VERSION ""

BS_:
BU_:

// =====================================================
// TX14 / CAN ID 0x11C / 284
// =====================================================
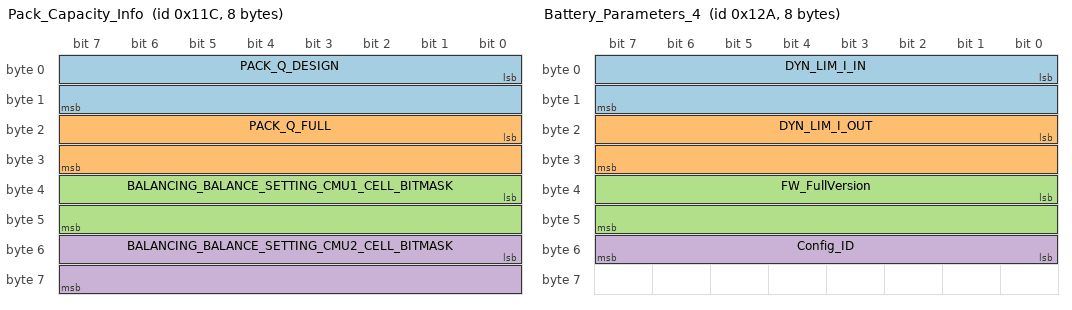
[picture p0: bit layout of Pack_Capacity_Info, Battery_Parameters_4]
BO_ 284 Pack_Capacity_Info: 8 Vector__XXX
 SG_ PACK_Q_DESIGN : 0|16@1+ (0.1,0) [0|180] "Ah" Vector__XXX
 SG_ PACK_Q_FULL   : 16|16@1+ (0.1,0) [0|180] "Ah" Vector__XXX
 SG_ BALANCING_BALANCE_SETTING_CMU1_CELL_BITMASK : 32|16@1+ (0.1,0) [0|6553.5] "mV" Vector__XXX
 SG_ BALANCING_BALANCE_SETTING_CMU2_CELL_BITMASK : 48|16@1+ (0.1,0) [0|6553.5] "mV" Vector__XXX

// =====================================================
// TX11 / CAN ID 0x12A / 298
// =====================================================
BO_ 298 Battery_Parameters_4: 8 Vector__XXX
 SG_ DYN_LIM_I_IN   : 0|16@1+ (0.1,0) [0|6553.5] "A" Vector__XXX
 SG_ DYN_LIM_I_OUT  : 16|16@1+ (0.1,0) [0|6553.5] "A" Vector__XXX
 SG_ FW_FullVersion: 32|16@1+ (1,0) [0|65535] "" Vector__XXX
 SG_ Config_ID     : 48|8@1+  (1,0) [0|255] "" Vector__XXX

// =====================================================
// TX9 / CAN ID 0x118 / 280
// =====================================================
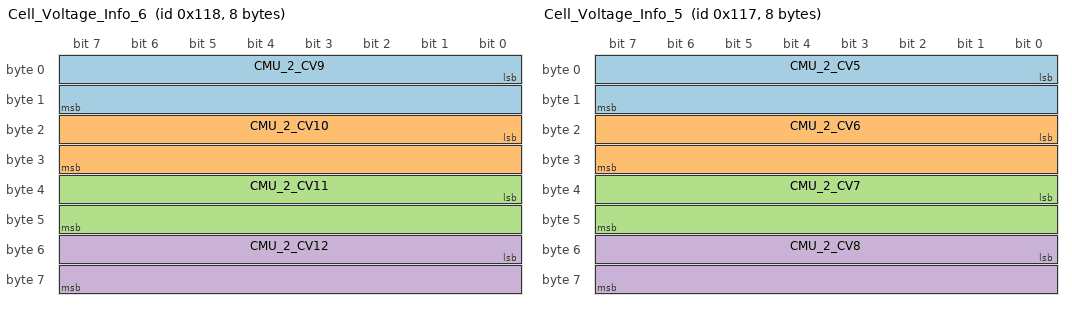
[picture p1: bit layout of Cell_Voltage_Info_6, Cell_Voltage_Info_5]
BO_ 280 Cell_Voltage_Info_6: 8 Vector__XXX
 SG_ CMU_2_CV9  : 0|16@1+ (0.1,0) [0|6553.5] "mV" Vector__XXX
 SG_ CMU_2_CV10 : 16|16@1+ (0.1,0) [0|6553.5] "mV" Vector__XXX
 SG_ CMU_2_CV11 : 32|16@1+ (0.1,0) [0|6553.5] "mV" Vector__XXX
 SG_ CMU_2_CV12 : 48|16@1+ (0.1,0) [0|6553.5] "mV" Vector__XXX

// =====================================================
// TX8 / CAN ID 0x117 / 279
// =====================================================
BO_ 279 Cell_Voltage_Info_5: 8 Vector__XXX
 SG_ CMU_2_CV5 : 0|16@1+ (0.1,0) [0|6553.5] "mV" Vector__XXX
 SG_ CMU_2_CV6 : 16|16@1+ (0.1,0) [0|6553.5] "mV" Vector__XXX
 SG_ CMU_2_CV7 : 32|16@1+ (0.1,0) [0|6553.5] "mV" Vector__XXX
 SG_ CMU_2_CV8 : 48|16@1+ (0.1,0) [0|6553.5] "mV" Vector__XXX

// =====================================================
// TX7 / CAN ID 0x116 / 278
// =====================================================
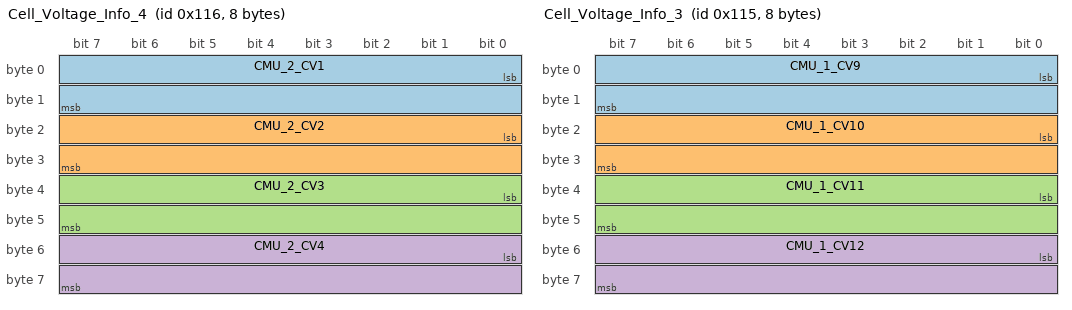
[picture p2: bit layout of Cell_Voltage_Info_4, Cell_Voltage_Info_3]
BO_ 278 Cell_Voltage_Info_4: 8 Vector__XXX
 SG_ CMU_2_CV1 : 0|16@1+ (0.1,0) [0|6553.5] "mV" Vector__XXX
 SG_ CMU_2_CV2 : 16|16@1+ (0.1,0) [0|6553.5] "mV" Vector__XXX
 SG_ CMU_2_CV3 : 32|16@1+ (0.1,0) [0|6553.5] "mV" Vector__XXX
 SG_ CMU_2_CV4 : 48|16@1+ (0.1,0) [0|6553.5] "mV" Vector__XXX

// =====================================================
// TX6 / CAN ID 0x115 / 277
// =====================================================
BO_ 277 Cell_Voltage_Info_3: 8 Vector__XXX
 SG_ CMU_1_CV9  : 0|16@1+ (0.1,0) [0|6553.5] "mV" Vector__XXX
 SG_ CMU_1_CV10 : 16|16@1+ (0.1,0) [0|6553.5] "mV" Vector__XXX
 SG_ CMU_1_CV11 : 32|16@1+ (0.1,0) [0|6553.5] "mV" Vector__XXX
 SG_ CMU_1_CV12 : 48|16@1+ (0.1,0) [0|6553.5] "mV" Vector__XXX

// =====================================================
// TX5 / CAN ID 0x114 / 276
// =====================================================
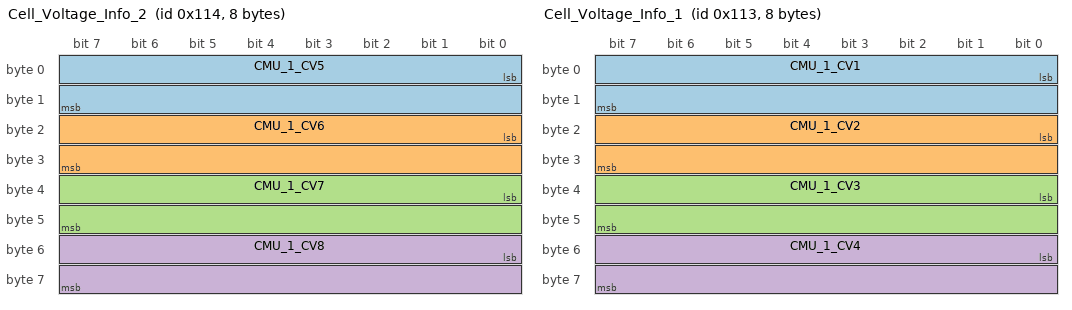
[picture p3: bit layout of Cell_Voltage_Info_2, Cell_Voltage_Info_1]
BO_ 276 Cell_Voltage_Info_2: 8 Vector__XXX
 SG_ CMU_1_CV5 : 0|16@1+ (0.1,0) [0|6553.5] "mV" Vector__XXX
 SG_ CMU_1_CV6 : 16|16@1+ (0.1,0) [0|6553.5] "mV" Vector__XXX
 SG_ CMU_1_CV7 : 32|16@1+ (0.1,0) [0|6553.5] "mV" Vector__XXX
 SG_ CMU_1_CV8 : 48|16@1+ (0.1,0) [0|6553.5] "mV" Vector__XXX

// =====================================================
// TX4 / CAN ID 0x113 / 275
// =====================================================
BO_ 275 Cell_Voltage_Info_1: 8 Vector__XXX
 SG_ CMU_1_CV1 : 0|16@1+ (0.1,0) [0|6553.5] "mV" Vector__XXX
 SG_ CMU_1_CV2 : 16|16@1+ (0.1,0) [0|6553.5] "mV" Vector__XXX
 SG_ CMU_1_CV3 : 32|16@1+ (0.1,0) [0|6553.5] "mV" Vector__XXX
 SG_ CMU_1_CV4 : 48|16@1+ (0.1,0) [0|6553.5] "mV" Vector__XXX

// =====================================================
// TX3 / CAN ID 0x112 / 274
// =====================================================
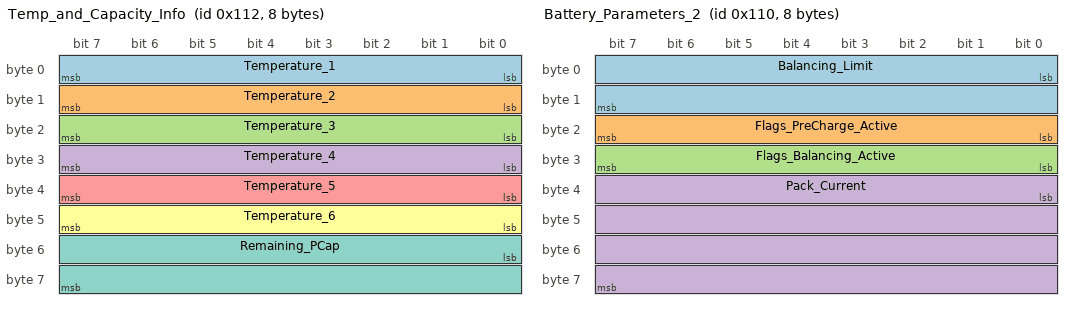
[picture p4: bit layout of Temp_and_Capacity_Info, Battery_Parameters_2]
BO_ 274 Temp_and_Capacity_Info: 8 Vector__XXX
 SG_ Temperature_1  : 0|8@1- (1,0) [-128|127] "degC" Vector__XXX
 SG_ Temperature_2  : 8|8@1- (1,0) [-128|127] "degC" Vector__XXX
 SG_ Temperature_3  : 16|8@1- (1,0) [-128|127] "degC" Vector__XXX
 SG_ Temperature_4  : 24|8@1- (1,0) [-128|127] "degC" Vector__XXX
 SG_ Temperature_5  : 32|8@1- (1,0) [-128|127] "degC" Vector__XXX
 SG_ Temperature_6  : 40|8@1- (1,0) [-128|127] "degC" Vector__XXX
 SG_ Remaining_PCap : 48|16@1+ (0.1,0) [0|180] "Ah" Vector__XXX

// =====================================================
// TX1 / CAN ID 0x110 / 272
// =====================================================
BO_ 272 Battery_Parameters_2: 8 Vector__XXX
 SG_ Balancing_Limit          : 0|16@1+ (0.1,0) [0|6553.5] "mV" Vector__XXX
 SG_ Flags_PreCharge_Active   : 16|8@1+ (1,0) [0|255] "" Vector__XXX
 SG_ Flags_Balancing_Active   : 24|8@1+ (1,0) [0|255] "" Vector__XXX
 SG_ Pack_Current             : 32|32@1- (1e-005,0) [-21474.8|21474.8] "A" Vector__XXX

// =====================================================
// TX2 / CAN ID 0x109 / 265
// =====================================================
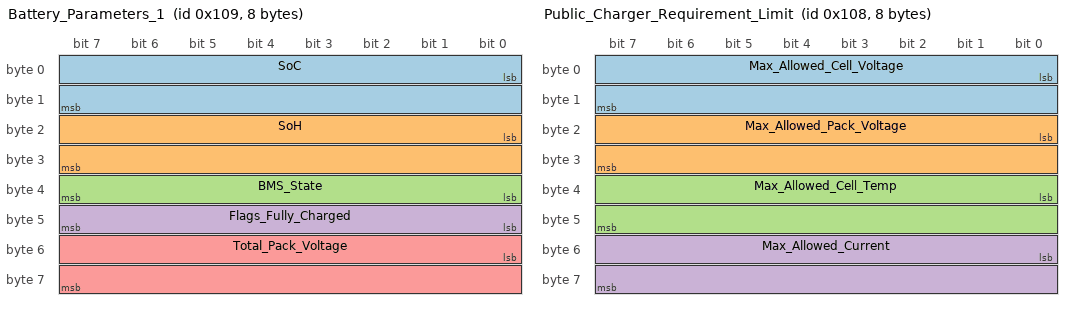
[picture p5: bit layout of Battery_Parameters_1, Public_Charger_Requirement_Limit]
BO_ 265 Battery_Parameters_1: 8 Vector__XXX
 SG_ SoC                 : 0|16@1+ (0.01,0) [0|655.35] "%" Vector__XXX
 SG_ SoH                 : 16|16@1+ (0.01,0) [0|655.35] "%" Vector__XXX
 SG_ BMS_State           : 32|8@1+ (1,0) [0|255] "" Vector__XXX
 SG_ Flags_Fully_Charged : 40|8@1+ (1,0) [0|255] "" Vector__XXX
 SG_ Total_Pack_Voltage  : 48|16@1+ (0.1,0) [0|6553.5] "V" Vector__XXX

// =====================================================
// TX12 / CAN ID 0x108 / 264
// =====================================================
BO_ 264 Public_Charger_Requirement_Limit: 8 Vector__XXX
 SG_ Max_Allowed_Cell_Voltage : 0|16@1+ (1,0) [0|65535] "mV" Vector__XXX
 SG_ Max_Allowed_Pack_Voltage : 16|16@1+ (1,0) [0|65535] "V" Vector__XXX
 SG_ Max_Allowed_Cell_Temp    : 32|16@1+ (1,0) [0|65535] "C" Vector__XXX
 SG_ Max_Allowed_Current      : 48|16@1+ (1,0) [0|65535] "A" Vector__XXX

// =====================================================
// Errors
// =====================================================

BO_ 600 Active_Error: 8 Vector__XXX
 SG_ Active_error_Count : 40|16@1+ (1,0) [0|65535] "" Vector__XXX

BO_ 602 Error_Code_1: 8 Vector__XXX
 SG_ Error_Code_1 : 55|16@0+ (1,0) [0|65535] "" Vector__XXX

BO_ 603 Error_Code_2: 8 Vector__XXX
 SG_ Error_Code_2 : 55|16@0+ (1,0) [0|65535] "" Vector__XXX

BO_ 604 Error_Code_3: 8 Vector__XXX
 SG_ Error_Code_3 : 55|16@0+ (1,0) [0|65535] "" Vector__XXX

BO_ 605 Error_Code_4: 8 Vector__XXX
 SG_ Error_Code_4 : 55|16@0+ (1,0) [0|65535] "" Vector__XXX

BO_ 606 Error_Code_5: 8 Vector__XXX
 SG_ Error_Code_5 : 55|16@0+ (1,0) [0|65535] "" Vector__XXX

BO_ 607 Error_Code_6: 8 Vector__XXX
 SG_ Error_Code_6 : 55|16@0+ (1,0) [0|65535] "" Vector__XXX
